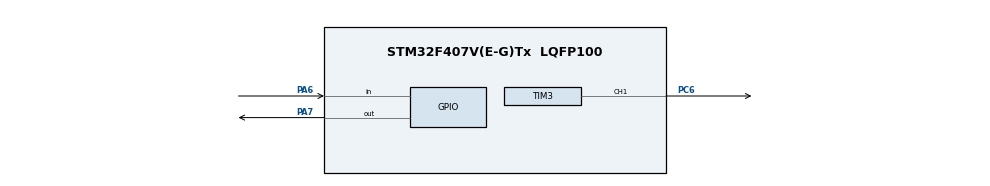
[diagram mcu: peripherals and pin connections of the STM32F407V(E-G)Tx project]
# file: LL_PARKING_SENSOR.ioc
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Mcu.Family=STM32F4
Mcu.Name=STM32F407V(E-G)Tx
Mcu.Package=LQFP100
NVIC.PriorityGroup=NVIC_PRIORITYGROUP_4
PA6.Signal=GPIO_Input
PA7.GPIO_Speed=GPIO_SPEED_FREQ_VERY_HIGH
PA7.Signal=GPIO_Output
PC6.Signal=S_TIM3_CH1
PH0-OSC_IN.Mode=HSE-External-Oscillator
PH0-OSC_IN.Signal=RCC_OSC_IN
PH1-OSC_OUT.Mode=HSE-External-Oscillator
PH1-OSC_OUT.Signal=RCC_OSC_OUT
ProjectManager.HeapSize=0x200
ProjectManager.StackSize=0x400
ProjectManager.TargetToolchain=STM32CubeIDE
RCC.48MHZClocksFreq_Value=84000000
RCC.AHBFreq_Value=168000000
RCC.APB1CLKDivider=RCC_HCLK_DIV4
RCC.APB1Freq_Value=42000000
RCC.APB1TimFreq_Value=84000000
RCC.APB2CLKDivider=RCC_HCLK_DIV2
RCC.APB2Freq_Value=84000000
RCC.APB2TimFreq_Value=168000000
RCC.CortexFreq_Value=168000000
RCC.HCLKFreq_Value=168000000
RCC.HSE_VALUE=8000000
RCC.HSI_VALUE=16000000
RCC.LSE_VALUE=32768
RCC.PLLM=4
RCC.PLLN=168
RCC.PLLSourceVirtual=RCC_PLLSOURCE_HSE
RCC.SYSCLKFreq_VALUE=168000000
RCC.SYSCLKSource=RCC_SYSCLKSOURCE_PLLCLK
RCC.VCOOutputFreq_Value=336000000
SH.S_TIM3_CH1.0=TIM3_CH1,PWM Generation1 CH1
TIM2.Period=0xFFFF
TIM2.Prescaler=83
TIM3.Channel-PWM\ Generation1\ CH1=TIM_CHANNEL_1
TIM3.Period=8399
TIM3.Prescaler=19999
TIM3.Pulse-PWM\ Generation1\ CH1=4199
VP_TIM2_VS_ClockSourceINT.Mode=Internal
VP_TIM3_VS_ClockSourceINT.Mode=Internal
board=custom

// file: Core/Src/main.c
/* USER CODE BEGIN Header */
/**
  ******************************************************************************
  * @file           : main.c
  * @brief          : Main program body
  ******************************************************************************
  * @attention
  *
  * Copyright (c) 2024 STMicroelectronics.
  * All rights reserved.
  *
  * This software is licensed under terms that can be found in the LICENSE file
  * in the root directory of this software component.
  * If no LICENSE file comes with this software, it is provided AS-IS.
  *
  ******************************************************************************
  */
/* USER CODE END Header */
#include "main.h"

/* USER CODE BEGIN Includes */

#include "stdio.h"
#include <string.h>
/* USER CODE END Includes */

void SystemClock_Config(void);
static void MX_GPIO_Init(void);
static void MX_TIM2_Init(void);
static void MX_TIM3_Init(void);

/* USER CODE BEGIN 0 */
uint16_t distance;
uint32_t sensor_time;
void delay_us(uint32_t us) {
    LL_TIM_SetCounter(TIM2, 0);
   while (LL_TIM_GetCounter(TIM2)<us );
}

uint16_t read_hcsr04()
{
	uint32_t local_time=0;
	LL_GPIO_SetOutputPin(GPIOA, LL_GPIO_PIN_7);
	delay_us(10);
	LL_GPIO_ResetOutputPin(GPIOA, LL_GPIO_PIN_7);

	while(!(LL_GPIO_IsInputPinSet(GPIOA, LL_GPIO_PIN_6)));
	while(LL_GPIO_IsInputPinSet(GPIOA, LL_GPIO_PIN_6))
	{
		local_time++;
		delay_us(1);
	}
	return local_time;
}

float map_frequency(uint16_t value, float in_min, float in_max, float out_min, float out_max) {
    float float_value = (float)value; // Integer değeri float'a dönüştür
    return (float_value - in_min) * (out_max - out_min) / (in_max - in_min) + out_min;
}

void buzzer_config(uint16_t distance_buzzer)
{
	if(distance_buzzer>40)
	{
		LL_TIM_SetPrescaler(TIM3, 19999);
	}
	else
	{
	float frequency=map_frequency(distance_buzzer, 1, 40, 10, 1);
	uint16_t prescaler=(10000/frequency)-1;
	LL_TIM_SetPrescaler(TIM3, prescaler);
	}
}
/* USER CODE END 0 */

int main(void)
{

  /* MCU Configuration--------------------------------------------------------*/

  /* Reset of all peripherals, Initializes the Flash interface and the Systick. */
  LL_APB2_GRP1_EnableClock(LL_APB2_GRP1_PERIPH_SYSCFG);
  LL_APB1_GRP1_EnableClock(LL_APB1_GRP1_PERIPH_PWR);

  /* System interrupt init*/
  NVIC_SetPriorityGrouping(NVIC_PRIORITYGROUP_4);

  /* SysTick_IRQn interrupt configuration */
  NVIC_SetPriority(SysTick_IRQn, NVIC_EncodePriority(NVIC_GetPriorityGrouping(),15, 0));

  /* Configure the system clock */
  SystemClock_Config();

  /* Initialize all configured peripherals */
  MX_GPIO_Init();
  MX_TIM2_Init();
  MX_TIM3_Init();
  /* USER CODE BEGIN 2 */
  LL_TIM_EnableCounter(TIM2);
  LL_TIM_EnableCounter(TIM3);
  LL_TIM_CC_EnableChannel(TIM3, LL_TIM_CHANNEL_CH1);
  LL_TIM_EnableAllOutputs(TIM3);

  /* USER CODE END 2 */

  /* Infinite loop */
  while (1)
  {

    /* USER CODE BEGIN 3 */
	  sensor_time=read_hcsr04();
	  distance=sensor_time/58;
	  buzzer_config(distance);
	  LL_mDelay(60);
  }
  /* USER CODE END 3 */
}

void SystemClock_Config(void)
{
  LL_FLASH_SetLatency(LL_FLASH_LATENCY_5);
  while(LL_FLASH_GetLatency()!= LL_FLASH_LATENCY_5)
  {
  }
  LL_PWR_SetRegulVoltageScaling(LL_PWR_REGU_VOLTAGE_SCALE1);
  LL_RCC_HSE_Enable();

   /* Wait till HSE is ready */
  while(LL_RCC_HSE_IsReady() != 1)
  {

  }
  LL_RCC_PLL_ConfigDomain_SYS(LL_RCC_PLLSOURCE_HSE, LL_RCC_PLLM_DIV_4, 168, LL_RCC_PLLP_DIV_2);
  LL_RCC_PLL_Enable();

   /* Wait till PLL is ready */
  while(LL_RCC_PLL_IsReady() != 1)
  {

  }
  while (LL_PWR_IsActiveFlag_VOS() == 0)
  {
  }
  LL_RCC_SetAHBPrescaler(LL_RCC_SYSCLK_DIV_1);
  LL_RCC_SetAPB1Prescaler(LL_RCC_APB1_DIV_4);
  LL_RCC_SetAPB2Prescaler(LL_RCC_APB2_DIV_2);
  LL_RCC_SetSysClkSource(LL_RCC_SYS_CLKSOURCE_PLL);

   /* Wait till System clock is ready */
  while(LL_RCC_GetSysClkSource() != LL_RCC_SYS_CLKSOURCE_STATUS_PLL)
  {

  }
  LL_Init1msTick(168000000);
  LL_SetSystemCoreClock(168000000);
}

static void MX_TIM2_Init(void)
{

  LL_TIM_InitTypeDef TIM_InitStruct = {0};

  /* Peripheral clock enable */
  LL_APB1_GRP1_EnableClock(LL_APB1_GRP1_PERIPH_TIM2);

  TIM_InitStruct.Prescaler = 83;
  TIM_InitStruct.CounterMode = LL_TIM_COUNTERMODE_UP;
  TIM_InitStruct.Autoreload = 0xFFFF;
  TIM_InitStruct.ClockDivision = LL_TIM_CLOCKDIVISION_DIV1;
  LL_TIM_Init(TIM2, &TIM_InitStruct);
  LL_TIM_DisableARRPreload(TIM2);
  LL_TIM_SetClockSource(TIM2, LL_TIM_CLOCKSOURCE_INTERNAL);
  LL_TIM_SetTriggerOutput(TIM2, LL_TIM_TRGO_RESET);
  LL_TIM_DisableMasterSlaveMode(TIM2);

}

static void MX_TIM3_Init(void)
{

  LL_TIM_InitTypeDef TIM_InitStruct = {0};
  LL_TIM_OC_InitTypeDef TIM_OC_InitStruct = {0};

  LL_GPIO_InitTypeDef GPIO_InitStruct = {0};

  /* Peripheral clock enable */
  LL_APB1_GRP1_EnableClock(LL_APB1_GRP1_PERIPH_TIM3);

  TIM_InitStruct.Prescaler = 19999;
  TIM_InitStruct.CounterMode = LL_TIM_COUNTERMODE_UP;
  TIM_InitStruct.Autoreload = 8399;
  TIM_InitStruct.ClockDivision = LL_TIM_CLOCKDIVISION_DIV1;
  LL_TIM_Init(TIM3, &TIM_InitStruct);
  LL_TIM_DisableARRPreload(TIM3);
  LL_TIM_SetClockSource(TIM3, LL_TIM_CLOCKSOURCE_INTERNAL);
  LL_TIM_OC_EnablePreload(TIM3, LL_TIM_CHANNEL_CH1);
  TIM_OC_InitStruct.OCMode = LL_TIM_OCMODE_PWM1;
  TIM_OC_InitStruct.OCState = LL_TIM_OCSTATE_DISABLE;
  TIM_OC_InitStruct.OCNState = LL_TIM_OCSTATE_DISABLE;
  TIM_OC_InitStruct.CompareValue = 4199;
  TIM_OC_InitStruct.OCPolarity = LL_TIM_OCPOLARITY_HIGH;
  LL_TIM_OC_Init(TIM3, LL_TIM_CHANNEL_CH1, &TIM_OC_InitStruct);
  LL_TIM_OC_DisableFast(TIM3, LL_TIM_CHANNEL_CH1);
  LL_TIM_SetTriggerOutput(TIM3, LL_TIM_TRGO_RESET);
  LL_TIM_DisableMasterSlaveMode(TIM3);
  LL_AHB1_GRP1_EnableClock(LL_AHB1_GRP1_PERIPH_GPIOC);
  /**TIM3 GPIO Configuration
  PC6   ------> TIM3_CH1
  */
  GPIO_InitStruct.Pin = LL_GPIO_PIN_6;
  GPIO_InitStruct.Mode = LL_GPIO_MODE_ALTERNATE;
  GPIO_InitStruct.Speed = LL_GPIO_SPEED_FREQ_LOW;
  GPIO_InitStruct.OutputType = LL_GPIO_OUTPUT_PUSHPULL;
  GPIO_InitStruct.Pull = LL_GPIO_PULL_NO;
  GPIO_InitStruct.Alternate = LL_GPIO_AF_2;
  LL_GPIO_Init(GPIOC, &GPIO_InitStruct);

}

static void MX_GPIO_Init(void)
{
  LL_GPIO_InitTypeDef GPIO_InitStruct = {0};

  /* GPIO Ports Clock Enable */
  LL_AHB1_GRP1_EnableClock(LL_AHB1_GRP1_PERIPH_GPIOH);
  LL_AHB1_GRP1_EnableClock(LL_AHB1_GRP1_PERIPH_GPIOA);
  LL_AHB1_GRP1_EnableClock(LL_AHB1_GRP1_PERIPH_GPIOC);

  /**/
  LL_GPIO_ResetOutputPin(GPIOA, LL_GPIO_PIN_7);

  /**/
  GPIO_InitStruct.Pin = LL_GPIO_PIN_6;
  GPIO_InitStruct.Mode = LL_GPIO_MODE_INPUT;
  GPIO_InitStruct.Pull = LL_GPIO_PULL_NO;
  LL_GPIO_Init(GPIOA, &GPIO_InitStruct);

  /**/
  GPIO_InitStruct.Pin = LL_GPIO_PIN_7;
  GPIO_InitStruct.Mode = LL_GPIO_MODE_OUTPUT;
  GPIO_InitStruct.Speed = LL_GPIO_SPEED_FREQ_VERY_HIGH;
  GPIO_InitStruct.OutputType = LL_GPIO_OUTPUT_PUSHPULL;
  GPIO_InitStruct.Pull = LL_GPIO_PULL_NO;
  LL_GPIO_Init(GPIOA, &GPIO_InitStruct);

}

void Error_Handler(void)
{
  __disable_irq();
  while (1)
  {
  }
}
